# dm646x_cslr_crgen register map
Vendor: Texas Instruments
Peripheral module from a debugger description file.
Registers are 32-bit, access not given, reset 0x0 unless marked. A register's access mark holds for its fields unless they carry their own. Offsets are as the file gives them; lines under a group give offsets from that group; [hi:lo] are bit positions; {n}, {i} and the like mark numbered series; 'fields as' and 'values as' point back to an identical list; <NAME> marks a mode.

## CRGEN
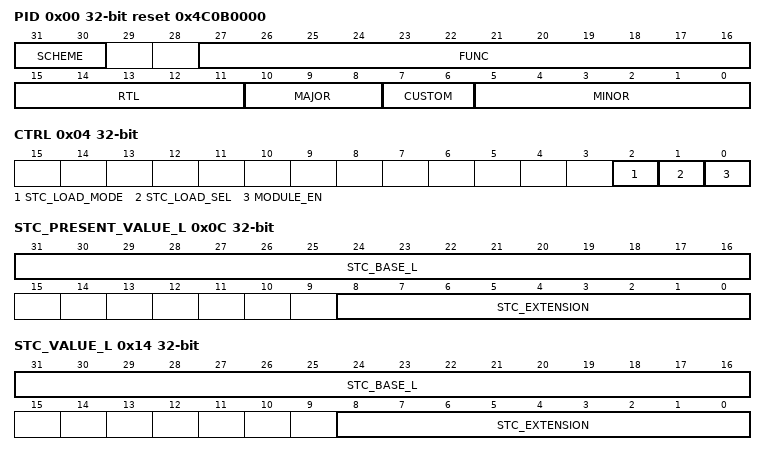
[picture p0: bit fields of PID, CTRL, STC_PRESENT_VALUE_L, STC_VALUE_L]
0x00 PID reset 0x4C0B0000 — CRGEN PID Register
  [31:30] SCHEME ro — Used to distinguish between old scheme and current. Spare bit to encode future schemes. Fixed to be "01"(b).
  [27:16] FUNC ro — Function indicates an S/W compatible module family. If there is not level of S/W compatibility, a new Func number (and hence PID) should be assigned.
  [15:11] RTL ro — Indicates RTL version, and must be easily ECO-able or controlled during fabrication. Ideally through a top level metal mask or e-fuse. This number is maintained / owned by IP design owner. In present design, fixed to be 0.
  [10:8] MAJOR ro — Local revision number which should be owned by module designer. This number should be updated for each major design change (such as bug fix, and memory size change etc ). In present design, fixed to be 0.
  [7:6] CUSTOM ro — Indicates a special version for a particular device. Consequence of use may avoid use of standard chip support library (CSL). In this module, fixed to be 0
  [5:0] MINOR ro — Local revision number which should be owned by module designer. This number should be updated for each small design change. In present design, fixed to be 0.
0x04 CTRL — CRGEN Control Register
  [2] STC_LOAD_MODE rw — This register defines loading mode for STC counter. 0 : Load PCR value on first loading pulse from SPIO 1 : Load PCR value on each loading pulse from SPIO
    0=ZERO (Load PCR value on first loading pulse from SPIO); 1=ONE (Load PCR value on each loading pulse from SPIO)
  [1] STC_LOAD_SEL rw — This register defines hold timing select for STC value. 0 : Pos edge of spio_i_pkt_strt of PCR packet (default) 1 : Pos edge of spio_crgen_pcr_en
    0=DISABLE (Pos edge of spio_i_pkt_strt of PCR packet (default)); 1=ENABLE (Pos edge of spio_crgen_pcr_en)
  [0] MODULE_EN rw — This bit can activate the module. The first "PCR loading" pulse after activating this register bit is used for initialize pulse of STC counter value. If user would like to stall this module when the module is activated, user needs to configure value of this bit to be 0. 0: CRGEN module doesn't work (stops). 1: CRGEN module works.
    0=INACTIVATE (CRGEN module doesn't work (stops).); 1=ACTIVATE (CRGEN module works.)
0x08 STC_PRESENT_VALUE_H — STC present base counter value Register
  [16:0] STC_BASE_H ro — STC base counter value which are driven in 90[KHz]. Higher 17 bits (32 to 16) are reflected to this register bits
0x0C STC_PRESENT_VALUE_L — STC present base counter value Register
  [31:16] STC_BASE_L ro — STC base counter value which are driven in 90[KHz]. Lower 16 bits (15 to 0) are reflected to this register bits.
  [8:0] STC_EXTENSION ro — STC extension counter value which is driven in 27[MHz] (maximum counter value is 299(unsigned) = 0x12B).
0x10 STC_VALUE_H — STC base counter value Register
  [16:0] STC_BASE_H ro — STC base counter value which are driven in 90[KHz]. Higher 17 bits (32 to 16) are reflected to this register bits.
0x14 STC_VALUE_L — STC base counter value Register
  [31:16] STC_BASE_L ro — STC base counter value which are driven in 90[KHz]. Lower 16 bits (15 to 0) are reflected to this register bits
  [8:0] STC_EXTENSION ro — STC extension counter value which is driven in 27[MHz] (maximum counter value is 299(unsigned) = 0x12B).
0x18 PCR_VALUE_H — PCR base counter value Register
  [16:0] PCR_BASE_H ro — PCR base counter value which are driven in 90[KHz]. Higher 17 bits (32 to 16) are reflected to this register bits.
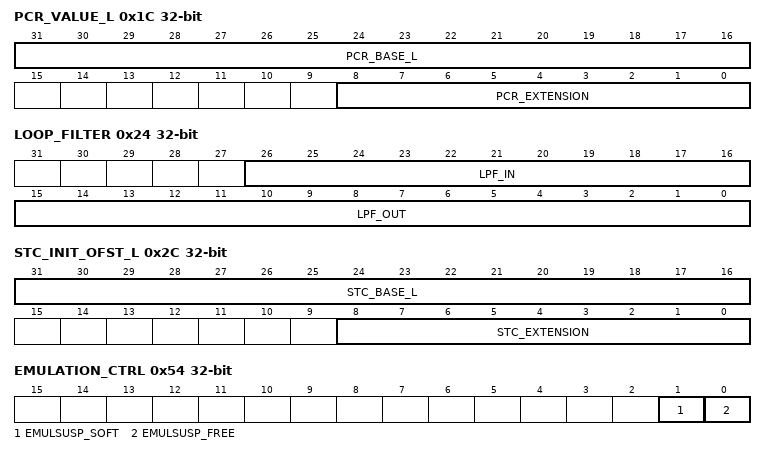
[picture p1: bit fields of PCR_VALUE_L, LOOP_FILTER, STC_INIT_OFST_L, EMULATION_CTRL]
0x1C PCR_VALUE_L — PCR base counter value Register
  [31:16] PCR_BASE_L ro — PCR base counter value which are driven in 90[KHz]. Lower 16 bits (15 to 0) are reflected to this register bits.
  [8:0] PCR_EXTENSION ro — PCR extension counter value which is driven in 27[MHz] (maximum counter value is 299(unsigned) = 0x12B).
0x20 PCR_PACKET_STATUS
  [3:0] PCR_PKT_STATUS ro — This register shows the status on PCR packet. Status value is detected by "PCR loading pulse" signal which comes from the SPIO module. [0] : Sync Byte Error flag. 1:Sync Byte Error, 0: No Error [1] : Transport Error Indicator in TS Header [2] : Discontinuity Indicator in adaptation field [3] : Fixed to "0"
0x24 LOOP_FILTER
  [26:16] LPF_IN ro — This register is prepared for reflecting subtraction result between PCR value and STC counter value. Result data is clipped into -1024~+1023 (11 bits).
  [15:0] LPF_OUT rw — This register is prepared for configuring loop filter output data which is derived from calculation result of ARM processor (-32768~+32767)
0x28 STC_INIT_OFST_H — STC base counter offset value upper Register
  [16:0] STC_BASE_H rw — STC base counter value which are driven in 90[KHz]. Higher 17 bits (32 to 16) are reflected to this register bits
0x2C STC_INIT_OFST_L — STC base counter offset value lower Register
  [31:16] STC_BASE_L rw — STC base counter value which are driven in 90[KHz]. Lower 16 bits (15 to 0) are reflected to this register bits.
  [8:0] STC_EXTENSION rw — STC extension counter value which is driven in 27[MHz] (maximum counter value is 299(unsigned) = 0x12B).
0x40 INTEN — Interrupt Enable register
  [0] INTEN rw — This bit controls preparation to activate interrupt from this module to ARM processor. If you would like to activate function of asserting interrupt to ARM, you should configure this bit to 1, and then you should also configure following "crgen_inten_set" register bit to 1. 0: Interrupt disable. 1: Interrupt enable.
    0=DISABLE (Interrupt disable.); 1=ENABLE (Interrupt enable)
0x44 INTEN_SET — Interrupt Enable register
  [0] INTEN_SET rw — If user would like to activate interrupt assertion function to ARM, user should configure this register bit to 1 with activating above "crgen_inten". During activated, this register value keeps 1. Please notice that this register has effect only when crgen_inten is activated. Otherwise, any configured value to this register is ignored, and register value stays at 0. User can write only '1', and cannot write '0' to this register. If user write 1 to "crgen_inten_clr" during this bit being activated, this bit is internally cleared to 0. 0: Interrupt inactivated (cannot write 0). 1: Interrupt activated.
    1=SET (Interrupt activated.)
0x48 INTEN_CLR — Interrupt Clear register
  [0] INTEN_CLR wo — If user would like to inactivate interrupt assertion function to ARM, user should configure this register bit to 1 with activating above "crgen_inten" and "crgen_inten_set". Please notice that this register has effect only when crgen_inten and crgen_inten_set are activated. Otherwise, any configured value to this register is ignored. Also, this register bit is write only register and user can write this register only value of 1 (cannot write 0). 0: No change. 1: Interrupt inactivated (cannot be read by ARM).
    1=CLR (Interrupt activated.)
0x4C STATUS
  [0] PCR_DETECT ro — Interrupt status register. This register works even if following interrupt register is inactivated. Please notice that this register is non-writable (read only). If you would like to clear this register, you should configure bit[0] in CRGEN_status_CLR register to 1. This status value is internally cleared if bit[0] in CRGEN_status_CLR is configured to 1. 0: PCR loading pulse is not detected so far. 1: PCR loading pulse is detected, and not checked yet.
    0=NOTDETECT (PCR loading pulse is not detected so far.); 1=DETECT (PCR loading pulse is detected, and not checked yet)
0x50 STATUS_CLR — Status register
  [0] PCR_DETECT_STATUS_CLR wo — Interrupt status clear register bit. If user would like to status register "pcr_detect", user should configure this register to be 1. Please notice that this register is "write-only", and written value cannot be read by ARM. 0: No change. 1: pcr_detect register clear (write only: cannot be read)
    1=CLR (pcr_detect register clear)
0x54 EMULATION_CTRL — Status register
  [1] EMULSUSP_SOFT rw — This bit defines whether or not a soft or hard stop is initiated whenever the "emususp" is asserted. 0: Hard Stop (the CRGEN module immediately stops processing). 1: Soft Stop (the CRGEN module stops processing after next PCR loading pulse is detected).
    0=HARD_STOP; 1=SOFT_STOP
  [0] EMULSUSP_FREE rw — This bit controls whether or not the peripheral will respond to the emulation suspend signal that it has been programmed to monitor. 0: functions based on configuration of "crgen_emulsusp_soft". 1: ignores any emulation suspend signal (non-stop).
    0=STOP (functions based on configuration of "crgen_emulsusp_soft".); 1=NON_STOP (ignores any emulation suspend signal (non-stop))
